# f280013x_dcc_regs register map
Vendor: Texas Instruments
Peripheral module from a debugger description file (folder C2000).
Address unit: 16 bits
Registers are 32-bit, read-write, no defined reset value unless marked. A register's access mark holds for its fields unless they carry their own. Offsets are as the file gives them; lines under a group give offsets from that group; [hi:lo] are bit positions; {n}, {i} and the like mark numbered series; 'fields as' and 'values as' point back to an identical list; <NAME> marks a mode.

## DCC_REGS — DCC Registers
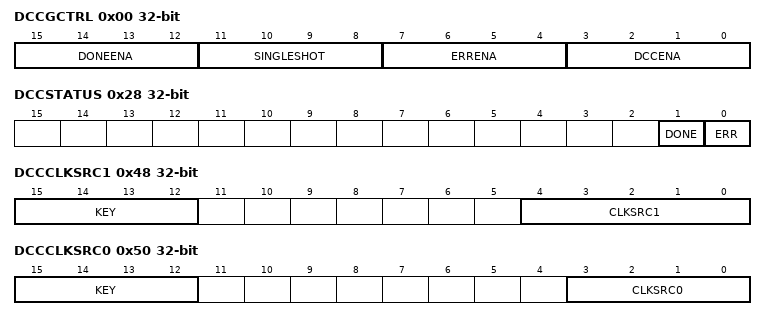
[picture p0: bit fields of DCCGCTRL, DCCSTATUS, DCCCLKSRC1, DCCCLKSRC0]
0x00 DCCGCTRL — Starts / stops the counters. Clears the error signal.
  [15:12] DONEENA — DONE Enable
  [11:8] SINGLESHOT — Single-Shot Enable
  [7:4] ERRENA — Error Enable
  [3:0] DCCENA — DCC Enable
0x10 DCCCNTSEED0 — Seed value for the counter attached to Clock Source 0.
  [19:0] COUNTSEED0 — Seed Value for Counter 0
0x18 DCCVALIDSEED0 — Seed value for the timeout counter attached to Clock Source 0.
  [15:0] VALIDSEED — Seed Value for Valid Duration Counter 0
0x20 DCCCNTSEED1 — Seed value for the counter attached to Clock Source 1.
  [19:0] COUNTSEED1 — Seed Value for Counter 1
0x28 DCCSTATUS — Specifies the status of the DCC Module.
  [1] DONE — Single-Shot Done Flag
  [0] ERR — Error Flag
0x30 DCCCNT0 ro — Value of the counter attached to Clock Source 0.
  [19:0] COUNT0 — Current Value of Counter 0
0x38 DCCVALID0 ro — Value of the valid counter attached to Clock Source 0.
  [15:0] VALID0 — Current Value of Valid 0
0x40 DCCCNT1 ro — Value of the counter attached to Clock Source 1.
  [19:0] COUNT1 — Current Value of Counter 1
0x48 DCCCLKSRC1 — Selects the clock source for Counter 1.
  [15:12] KEY — Enables or Disables Clock Source Selection for COUNT1
  [4:0] CLKSRC1 — Clock Source Select for Counter 1
0x50 DCCCLKSRC0 — Selects the clock source for Counter 0.
  [15:12] KEY — Enables or Disables Clock Source Selection for COUNT0
  [3:0] CLKSRC0 — Clock Source Select for Counter 0
